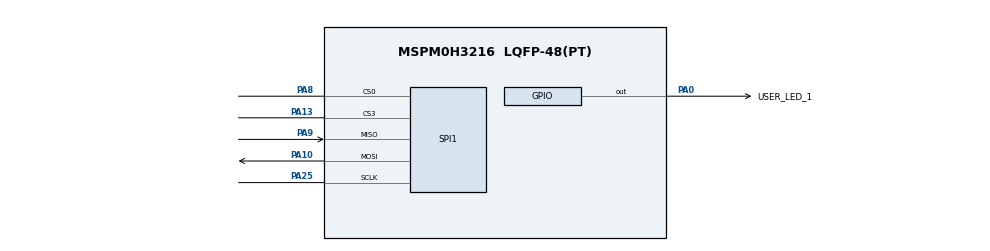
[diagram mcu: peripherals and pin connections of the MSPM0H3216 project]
//@cliArgs --device "MSPM0H3216" --package "LQFP-48(PT)" --part "Default"
//@v2CliArgs --device "MSPM0H3216" --package "LQFP-48(PT)"
// @cliArgs --board /ti/boards/LP_MSPM0H3216 --rtos nortos

/**
 * Import the modules used in this configuration.
 */
const GPIO   = scripting.addModule("/ti/driverlib/GPIO", {}, false);
const GPIO1  = GPIO.addInstance();
const SPI    = scripting.addModule("/ti/driverlib/SPI", {}, false);
const SPI1   = SPI.addInstance();
const SYSCTL = scripting.addModule("/ti/driverlib/SYSCTL");

/**
 * Write custom configuration values to the imported modules.
 */
GPIO1.$name                         = "GPIO_LEDS";
GPIO1.associatedPins[0].$name       = "USER_LED_1";
GPIO1.associatedPins[0].initialValue        = "SET";
GPIO1.associatedPins[0].pin.$assign = "PA0";

const Board = scripting.addModule("/ti/driverlib/Board", {}, false);

SPI1.targetBitRate              = 500000;
SPI1.spiClkSrc                  = "BUSCLK";
SPI1.enableCDMode               = true;
SPI1.$name                      = "SPI_0";
SPI1.peripheral.$assign         = "SPI0";
SPI1.peripheral.sclkPin.$assign = "PA25";
SPI1.peripheral.mosiPin.$assign = "PA10";
SPI1.peripheral.misoPin.$assign = "PA9";
SPI1.peripheral.cs0Pin.$assign  = "PA8";
SPI1.peripheral.cs3Pin.$assign  = "PA13";

SYSCTL.clockTreeEn = true;
SYSCTL.forceDefaultClkConfig = true;
